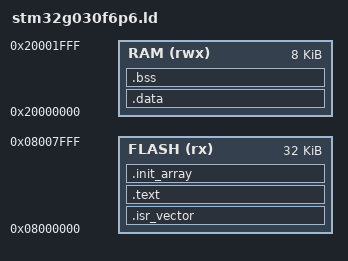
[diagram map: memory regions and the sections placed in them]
MEMORY
{
    FLASH (rx)  : ORIGIN = 0x08000000, LENGTH = 32K
    RAM   (rwx) : ORIGIN = 0x20000000, LENGTH = 8K
}

SECTIONS
{
    .isr_vector :
    {
        . = ALIGN(4);
        KEEP(*(.isr_vector))
        . = ALIGN(4);
    } > FLASH

    .text :
    {
        . = ALIGN(4);
        *(.text*)
        *(.rodata*)
        . = ALIGN(4);
        _etext = .;
    } > FLASH

    .init_array :
    {
        . = ALIGN(4);
        __init_array_start = .;
        KEEP(*(.init_array*))
        __init_array_end = .;
        . = ALIGN(4);
    } > FLASH

    _sidata = .;

    .data : AT (_sidata)
    {
        . = ALIGN(4);
        _sdata = .;
        *(.data*)
        . = ALIGN(4);
        _edata = .;
    } > RAM

    .bss :
    {
        . = ALIGN(4);
        _sbss = .;
        *(.bss*)
        *(COMMON)
        . = ALIGN(4);
        _ebss = .;
    } > RAM

    _estack = ORIGIN(RAM) + LENGTH(RAM);
}
